AUTOSAR XML (schema 00051)
standard types defined: UINT8, UINT16, UINT32, UINT64
package /Clusters
  can cluster CANFD_F: baudrate=500000, can-fd-baudrate=2000000
    can physical channel CANFD_F_CH
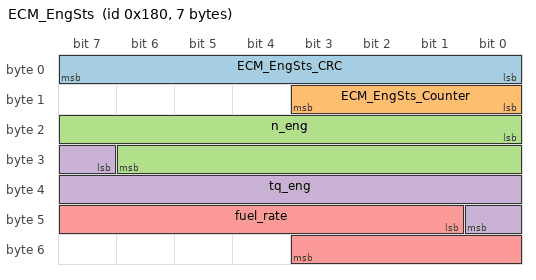
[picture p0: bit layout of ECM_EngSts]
      frame ECM_EngSts: id 0x180, from ECM, frame-length=7, can-addressing-mode=STANDARD, can-frame-rx-behavior=CAN-FD, can-frame-tx-behavior=CAN-FD
        pdu ECM_EngSts: length=7, minimum-delay=0.002, transmission-mode-true-timing={cyclic-timing=time-period=0.01, event-controlled-timing=number-of-repetitions=0}, unused-bit-pattern=255
          signal ECM_EngSts_CRC: start 0, 8 bit, little-endian, init-value=0, base-type=UINT8, transfer-property=PENDING
          signal ECM_EngSts_Counter: start 8, 4 bit, little-endian, init-value=0, base-type=UINT8, transfer-property=PENDING
          signal n_eng: start 16, 15 bit, little-endian, init-value=0, base-type=UINT16, compu {phys=raw*0.25 for raw 0..32767; unit rpm}, unit=rpm, transfer-property=TRIGGERED-ON-CHANGE
          signal tq_eng: start 31, 10 bit, little-endian, init-value=0, base-type=UINT16, compu {phys=raw*0.5-50 for raw 0..1023; unit N m}, unit=N m, transfer-property=TRIGGERED-ON-CHANGE
          signal fuel_rate: start 41, 11 bit, little-endian, init-value=0, base-type=UINT16, compu {phys=raw*0.01 for raw 0..2047; unit g/s}, unit=g/s, transfer-property=TRIGGERED-ON-CHANGE
      frame ECM_EngThm: id 0x182, from ECM, frame-length=2, can-addressing-mode=STANDARD, can-frame-rx-behavior=CAN-FD, can-frame-tx-behavior=CAN-FD
        pdu ECM_EngThm: length=2, transmission-mode-true-timing=cyclic-timing=time-period=0.1, unused-bit-pattern=255
          signal T_cool_eng: start 0, 8 bit, little-endian, init-value=0, base-type=UINT8, compu {phys=raw-40 for raw 0..255; unit degC}, unit=degC, transfer-property=PENDING
          signal T_cat: start 8, 8 bit, little-endian, init-value=0, base-type=UINT8, compu {phys=raw*5-40 for raw 0..255; unit degC}, unit=degC, transfer-property=PENDING
      frame PCU_MgSts: id 0x140, from PCU, frame-length=12, can-addressing-mode=STANDARD, can-frame-rx-behavior=CAN-FD, can-frame-tx-behavior=CAN-FD
        pdu PCU_MgSts: length=12, minimum-delay=0.002, transmission-mode-true-timing={cyclic-timing=time-period=0.01, event-controlled-timing=number-of-repetitions=0}, unused-bit-pattern=255
          signal PCU_MgSts_CRC: start 0, 8 bit, little-endian, init-value=0, base-type=UINT8, transfer-property=PENDING
          signal PCU_MgSts_Counter: start 8, 4 bit, little-endian, init-value=0, base-type=UINT8, transfer-property=PENDING
          signal n_MG1: start 16, 15 bit, little-endian, init-value=0, base-type=UINT16, compu {phys=raw-15000 for raw 0..32767; unit rpm}, unit=rpm, transfer-property=TRIGGERED-ON-CHANGE
          signal tq_MG1: start 31, 11 bit, little-endian, init-value=0, base-type=UINT16, compu {phys=raw*0.25-200 for raw 0..2047; unit N m}, unit=N m, transfer-property=TRIGGERED-ON-CHANGE
          signal n_MG2: start 42, 15 bit, little-endian, init-value=0, base-type=UINT16, compu {phys=raw-15000 for raw 0..32767; unit rpm}, unit=rpm, transfer-property=TRIGGERED-ON-CHANGE
          signal tq_MG2: start 57, 12 bit, little-endian, init-value=0, base-type=UINT16, compu {phys=raw*0.25-400 for raw 0..4095; unit N m}, unit=N m, transfer-property=TRIGGERED-ON-CHANGE
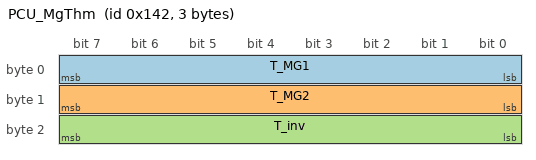
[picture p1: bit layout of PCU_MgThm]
      frame PCU_MgThm: id 0x142, from PCU, frame-length=3, can-addressing-mode=STANDARD, can-frame-rx-behavior=CAN-FD, can-frame-tx-behavior=CAN-FD
        pdu PCU_MgThm: length=3, transmission-mode-true-timing=cyclic-timing=time-period=0.1, unused-bit-pattern=255
          signal T_MG1: start 0, 8 bit, little-endian, init-value=0, base-type=UINT8, compu {phys=raw-40 for raw 0..255; unit degC}, unit=degC, transfer-property=PENDING
          signal T_MG2: start 8, 8 bit, little-endian, init-value=0, base-type=UINT8, compu {phys=raw-40 for raw 0..255; unit degC}, unit=degC, transfer-property=PENDING
          signal T_inv: start 16, 8 bit, little-endian, init-value=0, base-type=UINT8, compu {phys=raw-40 for raw 0..255; unit degC}, unit=degC, transfer-property=PENDING
      frame ESC_VehDyn: id 0x80, from ESC, frame-length=12, can-addressing-mode=STANDARD, can-frame-rx-behavior=CAN-FD, can-frame-tx-behavior=CAN-FD
        pdu ESC_VehDyn: length=12, transmission-mode-true-timing=cyclic-timing=time-period=0.01, unused-bit-pattern=255
          signal ESC_VehDyn_CRC: start 0, 8 bit, little-endian, init-value=0, base-type=UINT8, transfer-property=PENDING
          signal ESC_VehDyn_Counter: start 8, 4 bit, little-endian, init-value=0, base-type=UINT8, transfer-property=PENDING
          signal v_veh: start 16, 13 bit, little-endian, init-value=0, base-type=UINT16, compu {phys=raw*0.01 for raw 0..8191; unit m/s}, unit=m/s, transfer-property=PENDING
          signal a_long: start 29, 12 bit, little-endian, init-value=0, base-type=UINT16, compu {phys=raw*0.01-15 for raw 0..4095; unit m/s^2}, unit=m/s^2, transfer-property=PENDING
          signal a_lat: start 41, 12 bit, little-endian, init-value=0, base-type=UINT16, compu {phys=raw*0.01-15 for raw 0..4095; unit m/s^2}, unit=m/s^2, transfer-property=PENDING
          signal yaw_rate: start 53, 13 bit, little-endian, init-value=0, base-type=UINT16, compu {phys=raw*0.05-150 for raw 0..8191; unit deg/s}, unit=deg/s, transfer-property=PENDING
      frame ESC_WhlSpd: id 0x82, from ESC, frame-length=12, can-addressing-mode=STANDARD, can-frame-rx-behavior=CAN-FD, can-frame-tx-behavior=CAN-FD
        pdu ESC_WhlSpd: length=12, transmission-mode-true-timing=cyclic-timing=time-period=0.01, unused-bit-pattern=255
          signal ESC_WhlSpd_CRC: start 0, 8 bit, little-endian, init-value=0, base-type=UINT8, transfer-property=PENDING
          signal ESC_WhlSpd_Counter: start 8, 4 bit, little-endian, init-value=0, base-type=UINT8, transfer-property=PENDING
          signal w_FL: start 16, 14 bit, little-endian, init-value=0, base-type=UINT16, compu {phys=raw*0.03 for raw 0..16383; unit rad/s}, unit=rad/s, transfer-property=PENDING
          signal w_FR: start 30, 14 bit, little-endian, init-value=0, base-type=UINT16, compu {phys=raw*0.03 for raw 0..16383; unit rad/s}, unit=rad/s, transfer-property=PENDING
          signal w_RL: start 44, 14 bit, little-endian, init-value=0, base-type=UINT16, compu {phys=raw*0.03 for raw 0..16383; unit rad/s}, unit=rad/s, transfer-property=PENDING
          signal w_RR: start 58, 14 bit, little-endian, init-value=0, base-type=UINT16, compu {phys=raw*0.03 for raw 0..16383; unit rad/s}, unit=rad/s, transfer-property=PENDING
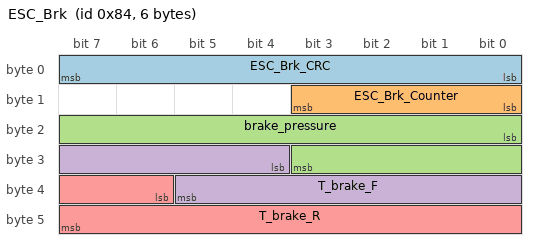
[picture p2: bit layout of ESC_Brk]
      frame ESC_Brk: id 0x84, from ESC, frame-length=6, can-addressing-mode=STANDARD, can-frame-rx-behavior=CAN-FD, can-frame-tx-behavior=CAN-FD
        pdu ESC_Brk: length=6, minimum-delay=0.005, transmission-mode-true-timing={cyclic-timing=time-period=0.02, event-controlled-timing=number-of-repetitions=0}, unused-bit-pattern=255
          signal ESC_Brk_CRC: start 0, 8 bit, little-endian, init-value=0, base-type=UINT8, transfer-property=PENDING
          signal ESC_Brk_Counter: start 8, 4 bit, little-endian, init-value=0, base-type=UINT8, transfer-property=PENDING
          signal brake_pressure: start 16, 12 bit, little-endian, init-value=0, base-type=UINT16, compu {phys=raw*0.1 for raw 0..4095; unit bar}, unit=bar, transfer-property=TRIGGERED-ON-CHANGE
          signal T_brake_F: start 28, 10 bit, little-endian, init-value=0, base-type=UINT16, compu {phys=raw-40 for raw 0..1023; unit degC}, unit=degC, transfer-property=TRIGGERED-ON-CHANGE
          signal T_brake_R: start 38, 10 bit, little-endian, init-value=0, base-type=UINT16, compu {phys=raw-40 for raw 0..1023; unit degC}, unit=degC, transfer-property=TRIGGERED-ON-CHANGE
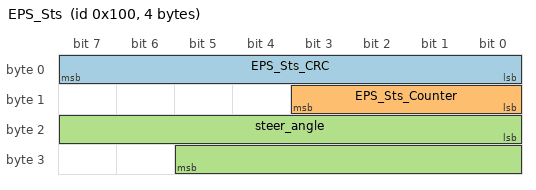
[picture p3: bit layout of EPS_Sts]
      frame EPS_Sts: id 0x100, from EPS, frame-length=4, can-addressing-mode=STANDARD, can-frame-rx-behavior=CAN-FD, can-frame-tx-behavior=CAN-FD
        pdu EPS_Sts: length=4, transmission-mode-true-timing=cyclic-timing=time-period=0.01, unused-bit-pattern=255
          signal EPS_Sts_CRC: start 0, 8 bit, little-endian, init-value=0, base-type=UINT8, transfer-property=PENDING
          signal EPS_Sts_Counter: start 8, 4 bit, little-endian, init-value=0, base-type=UINT8, transfer-property=PENDING
          signal steer_angle: start 16, 14 bit, little-endian, init-value=0, base-type=UINT16, compu {phys=raw*0.1-800 for raw 0..16383; unit deg}, unit=deg, transfer-property=PENDING
      frame DCDC_Sts: id 0x300, from DCDC_ECU, frame-length=3, can-addressing-mode=STANDARD, can-frame-rx-behavior=CAN-FD, can-frame-tx-behavior=CAN-FD
        pdu DCDC_Sts: length=3, minimum-delay=0.01, transmission-mode-true-timing={cyclic-timing=time-period=0.1, event-controlled-timing=number-of-repetitions=0}, unused-bit-pattern=255
          signal V_12: start 0, 11 bit, little-endian, init-value=0, base-type=UINT16, compu {phys=raw*0.01 for raw 0..2047; unit V}, unit=V, transfer-property=TRIGGERED-ON-CHANGE
          signal I_dcdc: start 11, 12 bit, little-endian, init-value=0, base-type=UINT16, compu {phys=raw*0.1 for raw 0..4095; unit A}, unit=A, transfer-property=TRIGGERED-ON-CHANGE
      frame TMS_Sts: id 0x340, from TMS, frame-length=3, can-addressing-mode=STANDARD, can-frame-rx-behavior=CAN-FD, can-frame-tx-behavior=CAN-FD
        pdu TMS_Sts: length=3, transmission-mode-true-timing=cyclic-timing=time-period=0.1, unused-bit-pattern=255
          signal T_cool_edu: start 0, 9 bit, little-endian, init-value=0, base-type=UINT16, compu {phys=raw*0.5-40 for raw 0..511; unit degC}, unit=degC, transfer-property=PENDING
          signal T_rad_out: start 9, 8 bit, little-endian, init-value=0, base-type=UINT8, compu {phys=raw-40 for raw 0..255; unit degC}, unit=degC, transfer-property=PENDING
      frame ZCF_TqReqEng: id 0xC0, from ZC_FRONT, frame-length=8, can-addressing-mode=STANDARD, can-frame-rx-behavior=CAN-FD, can-frame-tx-behavior=CAN-FD
        pdu ZCF_TqReqEng: length=8, transmission-mode-true-timing=cyclic-timing=time-period=0.01, unused-bit-pattern=255
          signal ZCF_TqReqEng_CRC: start 0, 8 bit, little-endian, init-value=0, base-type=UINT8, transfer-property=PENDING
          signal ZCF_TqReqEng_Counter: start 8, 4 bit, little-endian, init-value=0, base-type=UINT8, transfer-property=PENDING
      frame ZCF_TqReqMg: id 0xC2, from ZC_FRONT, frame-length=8, can-addressing-mode=STANDARD, can-frame-rx-behavior=CAN-FD, can-frame-tx-behavior=CAN-FD
        pdu ZCF_TqReqMg: length=8, transmission-mode-true-timing=cyclic-timing=time-period=0.01, unused-bit-pattern=255
          signal ZCF_TqReqMg_CRC: start 0, 8 bit, little-endian, init-value=0, base-type=UINT8, transfer-property=PENDING
          signal ZCF_TqReqMg_Counter: start 8, 4 bit, little-endian, init-value=0, base-type=UINT8, transfer-property=PENDING
      frame ZCF_ThmReq: id 0xC4, from ZC_FRONT, frame-length=8, can-addressing-mode=STANDARD, can-frame-rx-behavior=CAN-FD, can-frame-tx-behavior=CAN-FD
        pdu ZCF_ThmReq: length=8, transmission-mode-true-timing=cyclic-timing=time-period=0.1, unused-bit-pattern=255
          signal ZCF_ThmReq_Payload: start 0, 64 bit, little-endian, init-value=0, base-type=UINT64, transfer-property=PENDING
      frame ECM_Bg0: id 0x4AA, from ECM, frame-length=8, can-addressing-mode=STANDARD, can-frame-rx-behavior=CAN-FD, can-frame-tx-behavior=CAN-FD
        pdu ECM_Bg0: length=8, transmission-mode-true-timing=cyclic-timing=time-period=0.2, unused-bit-pattern=255
          signal ECM_Bg0_Payload: start 0, 64 bit, little-endian, init-value=0, base-type=UINT64, transfer-property=PENDING
      frame ECM_Bg1: id 0x196, from ECM, frame-length=24, can-addressing-mode=STANDARD, can-frame-rx-behavior=CAN-FD, can-frame-tx-behavior=CAN-FD
        pdu ECM_Bg1: length=24, transmission-mode-true-timing=cyclic-timing=time-period=0.01, unused-bit-pattern=255
          signal ECM_Bg1_Payload: start 0, 64 bit, little-endian, init-value=0, base-type=UINT64, transfer-property=PENDING
      frame ECM_Bg2: id 0x198, from ECM, frame-length=16, can-addressing-mode=STANDARD, can-frame-rx-behavior=CAN-FD, can-frame-tx-behavior=CAN-FD
        pdu ECM_Bg2: length=16, transmission-mode-true-timing=cyclic-timing=time-period=0.05, unused-bit-pattern=255
          signal ECM_Bg2_Payload: start 0, 64 bit, little-endian, init-value=0, base-type=UINT64, transfer-property=PENDING
      frame ECM_Bg3: id 0x19A, from ECM, frame-length=16, can-addressing-mode=STANDARD, can-frame-rx-behavior=CAN-FD, can-frame-tx-behavior=CAN-FD
        pdu ECM_Bg3: length=16, transmission-mode-true-timing=cyclic-timing=time-period=0.01, unused-bit-pattern=255
          signal ECM_Bg3_Payload: start 0, 64 bit, little-endian, init-value=0, base-type=UINT64, transfer-property=PENDING
      frame ECM_Bg4: id 0x4B2, from ECM, frame-length=16, can-addressing-mode=STANDARD, can-frame-rx-behavior=CAN-FD, can-frame-tx-behavior=CAN-FD
        pdu ECM_Bg4: length=16, transmission-mode-true-timing=cyclic-timing=time-period=0.1, unused-bit-pattern=255
          signal ECM_Bg4_Payload: start 0, 64 bit, little-endian, init-value=0, base-type=UINT64, transfer-property=PENDING
      frame ECM_Bg5: id 0x4B4, from ECM, frame-length=32, can-addressing-mode=STANDARD, can-frame-rx-behavior=CAN-FD, can-frame-tx-behavior=CAN-FD
        pdu ECM_Bg5: length=32, transmission-mode-true-timing=cyclic-timing=time-period=0.2, unused-bit-pattern=255
          signal ECM_Bg5_Payload: start 0, 64 bit, little-endian, init-value=0, base-type=UINT64, transfer-property=PENDING
      frame ECM_Bg6: id 0x4B6, from ECM, frame-length=64, can-addressing-mode=STANDARD, can-frame-rx-behavior=CAN-FD, can-frame-tx-behavior=CAN-FD
        pdu ECM_Bg6: length=64, transmission-mode-true-timing=cyclic-timing=time-period=0.1, unused-bit-pattern=255
          signal ECM_Bg6_Payload: start 0, 64 bit, little-endian, init-value=0, base-type=UINT64, transfer-property=PENDING
      frame ECM_NM: id 0x700, from ECM, frame-length=8, can-addressing-mode=STANDARD, can-frame-rx-behavior=CAN-FD, can-frame-tx-behavior=CAN-FD
        pdu ECM_NM: length=8, transmission-mode-true-timing=cyclic-timing=time-period=1, unused-bit-pattern=255
          signal ECM_NM_Payload: start 0, 64 bit, little-endian, init-value=0, base-type=UINT64, transfer-property=PENDING
      frame PCU_Bg0: id 0x4BA, from PCU, frame-length=8, can-addressing-mode=STANDARD, can-frame-rx-behavior=CAN-FD, can-frame-tx-behavior=CAN-FD
        pdu PCU_Bg0: length=8, transmission-mode-true-timing=cyclic-timing=time-period=0.2, unused-bit-pattern=255
          signal PCU_Bg0_Payload: start 0, 64 bit, little-endian, init-value=0, base-type=UINT64, transfer-property=PENDING
      frame PCU_Bg1: id 0x4BC, from PCU, frame-length=24, can-addressing-mode=STANDARD, can-frame-rx-behavior=CAN-FD, can-frame-tx-behavior=CAN-FD
        pdu PCU_Bg1: length=24, transmission-mode-true-timing=cyclic-timing=time-period=0.5, unused-bit-pattern=255
          signal PCU_Bg1_Payload: start 0, 64 bit, little-endian, init-value=0, base-type=UINT64, transfer-property=PENDING
      frame PCU_Bg2: id 0x158, from PCU, frame-length=8, can-addressing-mode=STANDARD, can-frame-rx-behavior=CAN-FD, can-frame-tx-behavior=CAN-FD
        pdu PCU_Bg2: length=8, transmission-mode-true-timing=cyclic-timing=time-period=0.01, unused-bit-pattern=255
          signal PCU_Bg2_Payload: start 0, 64 bit, little-endian, init-value=0, base-type=UINT64, transfer-property=PENDING
      frame PCU_Bg3: id 0x15A, from PCU, frame-length=64, can-addressing-mode=STANDARD, can-frame-rx-behavior=CAN-FD, can-frame-tx-behavior=CAN-FD
        pdu PCU_Bg3: length=64, transmission-mode-true-timing=cyclic-timing=time-period=0.02, unused-bit-pattern=255
          signal PCU_Bg3_Payload: start 0, 64 bit, little-endian, init-value=0, base-type=UINT64, transfer-property=PENDING
      frame PCU_Bg4: id 0x4C2, from PCU, frame-length=64, can-addressing-mode=STANDARD, can-frame-rx-behavior=CAN-FD, can-frame-tx-behavior=CAN-FD
        pdu PCU_Bg4: length=64, transmission-mode-true-timing=cyclic-timing=time-period=0.2, unused-bit-pattern=255
          signal PCU_Bg4_Payload: start 0, 64 bit, little-endian, init-value=0, base-type=UINT64, transfer-property=PENDING
      frame PCU_Bg5: id 0x15E, from PCU, frame-length=24, can-addressing-mode=STANDARD, can-frame-rx-behavior=CAN-FD, can-frame-tx-behavior=CAN-FD
        pdu PCU_Bg5: length=24, transmission-mode-true-timing=cyclic-timing=time-period=0.02, unused-bit-pattern=255
          signal PCU_Bg5_Payload: start 0, 64 bit, little-endian, init-value=0, base-type=UINT64, transfer-property=PENDING
      frame PCU_NM: id 0x701, from PCU, frame-length=8, can-addressing-mode=STANDARD, can-frame-rx-behavior=CAN-FD, can-frame-tx-behavior=CAN-FD
        pdu PCU_NM: length=8, transmission-mode-true-timing=cyclic-timing=time-period=1, unused-bit-pattern=255
          signal PCU_NM_Payload: start 0, 64 bit, little-endian, init-value=0, base-type=UINT64, transfer-property=PENDING
      frame ESC_Bg0: id 0x4C8, from ESC, frame-length=32, can-addressing-mode=STANDARD, can-frame-rx-behavior=CAN-FD, can-frame-tx-behavior=CAN-FD
        pdu ESC_Bg0: length=32, transmission-mode-true-timing=cyclic-timing=time-period=0.1, unused-bit-pattern=255
          signal ESC_Bg0_Payload: start 0, 64 bit, little-endian, init-value=0, base-type=UINT64, transfer-property=PENDING
      frame ESC_Bg1: id 0x98, from ESC, frame-length=24, can-addressing-mode=STANDARD, can-frame-rx-behavior=CAN-FD, can-frame-tx-behavior=CAN-FD
        pdu ESC_Bg1: length=24, transmission-mode-true-timing=cyclic-timing=time-period=0.01, unused-bit-pattern=255
          signal ESC_Bg1_Payload: start 0, 64 bit, little-endian, init-value=0, base-type=UINT64, transfer-property=PENDING
      frame ESC_Bg2: id 0x4CC, from ESC, frame-length=32, can-addressing-mode=STANDARD, can-frame-rx-behavior=CAN-FD, can-frame-tx-behavior=CAN-FD
        pdu ESC_Bg2: length=32, transmission-mode-true-timing=cyclic-timing=time-period=0.1, unused-bit-pattern=255
          signal ESC_Bg2_Payload: start 0, 64 bit, little-endian, init-value=0, base-type=UINT64, transfer-property=PENDING
      frame ESC_Bg3: id 0x4CE, from ESC, frame-length=16, can-addressing-mode=STANDARD, can-frame-rx-behavior=CAN-FD, can-frame-tx-behavior=CAN-FD
        pdu ESC_Bg3: length=16, transmission-mode-true-timing=cyclic-timing=time-period=0.1, unused-bit-pattern=255
          signal ESC_Bg3_Payload: start 0, 64 bit, little-endian, init-value=0, base-type=UINT64, transfer-property=PENDING
      frame ESC_Bg4: id 0x4D0, from ESC, frame-length=16, can-addressing-mode=STANDARD, can-frame-rx-behavior=CAN-FD, can-frame-tx-behavior=CAN-FD
        pdu ESC_Bg4: length=16, transmission-mode-true-timing=cyclic-timing=time-period=0.1, unused-bit-pattern=255
          signal ESC_Bg4_Payload: start 0, 64 bit, little-endian, init-value=0, base-type=UINT64, transfer-property=PENDING
      frame ESC_Bg5: id 0xA0, from ESC, frame-length=8, can-addressing-mode=STANDARD, can-frame-rx-behavior=CAN-FD, can-frame-tx-behavior=CAN-FD
        pdu ESC_Bg5: length=8, transmission-mode-true-timing=cyclic-timing=time-period=0.02, unused-bit-pattern=255
          signal ESC_Bg5_Payload: start 0, 64 bit, little-endian, init-value=0, base-type=UINT64, transfer-property=PENDING
      frame ESC_Bg6: id 0xA2, from ESC, frame-length=8, can-addressing-mode=STANDARD, can-frame-rx-behavior=CAN-FD, can-frame-tx-behavior=CAN-FD
        pdu ESC_Bg6: length=8, transmission-mode-true-timing=cyclic-timing=time-period=0.02, unused-bit-pattern=255
          signal ESC_Bg6_Payload: start 0, 64 bit, little-endian, init-value=0, base-type=UINT64, transfer-property=PENDING
      frame ESC_Bg7: id 0x4D6, from ESC, frame-length=24, can-addressing-mode=STANDARD, can-frame-rx-behavior=CAN-FD, can-frame-tx-behavior=CAN-FD
        pdu ESC_Bg7: length=24, transmission-mode-true-timing=cyclic-timing=time-period=0.2, unused-bit-pattern=255
          signal ESC_Bg7_Payload: start 0, 64 bit, little-endian, init-value=0, base-type=UINT64, transfer-property=PENDING
      frame ESC_NM: id 0x702, from ESC, frame-length=8, can-addressing-mode=STANDARD, can-frame-rx-behavior=CAN-FD, can-frame-tx-behavior=CAN-FD
        pdu ESC_NM: length=8, transmission-mode-true-timing=cyclic-timing=time-period=1, unused-bit-pattern=255
          signal ESC_NM_Payload: start 0, 64 bit, little-endian, init-value=0, base-type=UINT64, transfer-property=PENDING
      frame EPS_Bg0: id 0x112, from EPS, frame-length=16, can-addressing-mode=STANDARD, can-frame-rx-behavior=CAN-FD, can-frame-tx-behavior=CAN-FD
        pdu EPS_Bg0: length=16, transmission-mode-true-timing=cyclic-timing=time-period=0.01, unused-bit-pattern=255
          signal EPS_Bg0_Payload: start 0, 64 bit, little-endian, init-value=0, base-type=UINT64, transfer-property=PENDING
      frame EPS_Bg1: id 0x114, from EPS, frame-length=24, can-addressing-mode=STANDARD, can-frame-rx-behavior=CAN-FD, can-frame-tx-behavior=CAN-FD
        pdu EPS_Bg1: length=24, transmission-mode-true-timing=cyclic-timing=time-period=0.02, unused-bit-pattern=255
          signal EPS_Bg1_Payload: start 0, 64 bit, little-endian, init-value=0, base-type=UINT64, transfer-property=PENDING
      frame EPS_Bg2: id 0x4DE, from EPS, frame-length=8, can-addressing-mode=STANDARD, can-frame-rx-behavior=CAN-FD, can-frame-tx-behavior=CAN-FD
        pdu EPS_Bg2: length=8, transmission-mode-true-timing=cyclic-timing=time-period=0.2, unused-bit-pattern=255
          signal EPS_Bg2_Payload: start 0, 64 bit, little-endian, init-value=0, base-type=UINT64, transfer-property=PENDING
      frame EPS_Bg3: id 0x4E0, from EPS, frame-length=16, can-addressing-mode=STANDARD, can-frame-rx-behavior=CAN-FD, can-frame-tx-behavior=CAN-FD
        pdu EPS_Bg3: length=16, transmission-mode-true-timing=cyclic-timing=time-period=0.1, unused-bit-pattern=255
          signal EPS_Bg3_Payload: start 0, 64 bit, little-endian, init-value=0, base-type=UINT64, transfer-property=PENDING
      frame EPS_NM: id 0x703, from EPS, frame-length=8, can-addressing-mode=STANDARD, can-frame-rx-behavior=CAN-FD, can-frame-tx-behavior=CAN-FD
        pdu EPS_NM: length=8, transmission-mode-true-timing=cyclic-timing=time-period=1, unused-bit-pattern=255
          signal EPS_NM_Payload: start 0, 64 bit, little-endian, init-value=0, base-type=UINT64, transfer-property=PENDING
      frame DCDC_ECU_Bg0: id 0x4E4, from DCDC_ECU, frame-length=16, can-addressing-mode=STANDARD, can-frame-rx-behavior=CAN-FD, can-frame-tx-behavior=CAN-FD
        pdu DCDC_ECU_Bg0: length=16, transmission-mode-true-timing=cyclic-timing=time-period=0.5, unused-bit-pattern=255
          signal DCDC_ECU_Bg0_Payload: start 0, 64 bit, little-endian, init-value=0, base-type=UINT64, transfer-property=PENDING
      frame DCDC_ECU_Bg1: id 0x314, from DCDC_ECU, frame-length=8, can-addressing-mode=STANDARD, can-frame-rx-behavior=CAN-FD, can-frame-tx-behavior=CAN-FD
        pdu DCDC_ECU_Bg1: length=8, transmission-mode-true-timing=cyclic-timing=time-period=0.02, unused-bit-pattern=255
          signal DCDC_ECU_Bg1_Payload: start 0, 64 bit, little-endian, init-value=0, base-type=UINT64, transfer-property=PENDING
      frame DCDC_ECU_Bg2: id 0x4E8, from DCDC_ECU, frame-length=24, can-addressing-mode=STANDARD, can-frame-rx-behavior=CAN-FD, can-frame-tx-behavior=CAN-FD
        pdu DCDC_ECU_Bg2: length=24, transmission-mode-true-timing=cyclic-timing=time-period=0.1, unused-bit-pattern=255
          signal DCDC_ECU_Bg2_Payload: start 0, 64 bit, little-endian, init-value=0, base-type=UINT64, transfer-property=PENDING
      frame DCDC_ECU_NM: id 0x704, from DCDC_ECU, frame-length=8, can-addressing-mode=STANDARD, can-frame-rx-behavior=CAN-FD, can-frame-tx-behavior=CAN-FD
        pdu DCDC_ECU_NM: length=8, transmission-mode-true-timing=cyclic-timing=time-period=1, unused-bit-pattern=255
          signal DCDC_ECU_NM_Payload: start 0, 64 bit, little-endian, init-value=0, base-type=UINT64, transfer-property=PENDING
      frame TMS_Bg0: id 0x352, from TMS, frame-length=16, can-addressing-mode=STANDARD, can-frame-rx-behavior=CAN-FD, can-frame-tx-behavior=CAN-FD
        pdu TMS_Bg0: length=16, transmission-mode-true-timing=cyclic-timing=time-period=0.05, unused-bit-pattern=255
          signal TMS_Bg0_Payload: start 0, 64 bit, little-endian, init-value=0, base-type=UINT64, transfer-property=PENDING
      frame TMS_Bg1: id 0x4EE, from TMS, frame-length=8, can-addressing-mode=STANDARD, can-frame-rx-behavior=CAN-FD, can-frame-tx-behavior=CAN-FD
        pdu TMS_Bg1: length=8, transmission-mode-true-timing=cyclic-timing=time-period=0.1, unused-bit-pattern=255
          signal TMS_Bg1_Payload: start 0, 64 bit, little-endian, init-value=0, base-type=UINT64, transfer-property=PENDING
      frame TMS_Bg2: id 0x4F0, from TMS, frame-length=8, can-addressing-mode=STANDARD, can-frame-rx-behavior=CAN-FD, can-frame-tx-behavior=CAN-FD
        pdu TMS_Bg2: length=8, transmission-mode-true-timing=cyclic-timing=time-period=0.5, unused-bit-pattern=255
          signal TMS_Bg2_Payload: start 0, 64 bit, little-endian, init-value=0, base-type=UINT64, transfer-property=PENDING
      frame TMS_Bg3: id 0x4F2, from TMS, frame-length=64, can-addressing-mode=STANDARD, can-frame-rx-behavior=CAN-FD, can-frame-tx-behavior=CAN-FD
        pdu TMS_Bg3: length=64, transmission-mode-true-timing=cyclic-timing=time-period=0.5, unused-bit-pattern=255
          signal TMS_Bg3_Payload: start 0, 64 bit, little-endian, init-value=0, base-type=UINT64, transfer-property=PENDING
      frame TMS_NM: id 0x705, from TMS, frame-length=8, can-addressing-mode=STANDARD, can-frame-rx-behavior=CAN-FD, can-frame-tx-behavior=CAN-FD
        pdu TMS_NM: length=8, transmission-mode-true-timing=cyclic-timing=time-period=1, unused-bit-pattern=255
          signal TMS_NM_Payload: start 0, 64 bit, little-endian, init-value=0, base-type=UINT64, transfer-property=PENDING
  can cluster CANFD_R: baudrate=500000, can-fd-baudrate=2000000
    can physical channel CANFD_R_CH
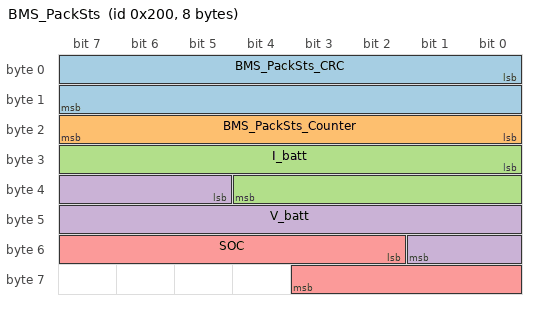
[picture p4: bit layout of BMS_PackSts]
      frame BMS_PackSts: id 0x200, from BMS, frame-length=8, can-addressing-mode=STANDARD, can-frame-rx-behavior=CAN-FD, can-frame-tx-behavior=CAN-FD
        pdu BMS_PackSts: length=8, minimum-delay=0.005, transmission-mode-true-timing={cyclic-timing=time-period=0.02, event-controlled-timing=number-of-repetitions=0}, unused-bit-pattern=255
          signal BMS_PackSts_CRC: start 0, 16 bit, little-endian, init-value=0, base-type=UINT16, transfer-property=PENDING
          signal BMS_PackSts_Counter: start 16, 8 bit, little-endian, init-value=0, base-type=UINT8, transfer-property=PENDING
          signal I_batt: start 24, 13 bit, little-endian, init-value=0, base-type=UINT16, compu {phys=raw*0.1-400 for raw 0..8191; unit A}, unit=A, transfer-property=TRIGGERED-ON-CHANGE
          signal V_batt: start 37, 13 bit, little-endian, init-value=0, base-type=UINT16, compu {phys=raw*0.1 for raw 0..8191; unit V}, unit=V, transfer-property=TRIGGERED-ON-CHANGE
          signal SOC: start 50, 10 bit, little-endian, init-value=0, base-type=UINT16, compu {phys=raw*0.1 for raw 0..1023; unit %}, unit=%, transfer-property=TRIGGERED-ON-CHANGE
      frame BMS_Thm: id 0x202, from BMS, frame-length=2, can-addressing-mode=STANDARD, can-frame-rx-behavior=CAN-FD, can-frame-tx-behavior=CAN-FD
        pdu BMS_Thm: length=2, transmission-mode-true-timing=cyclic-timing=time-period=0.1, unused-bit-pattern=255
          signal T_batt: start 0, 9 bit, little-endian, init-value=0, base-type=UINT16, compu {phys=raw*0.5-40 for raw 0..511; unit degC}, unit=degC, transfer-property=PENDING
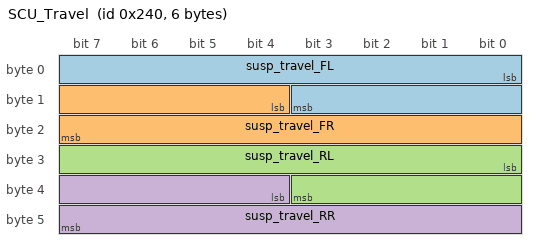
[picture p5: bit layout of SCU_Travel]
      frame SCU_Travel: id 0x240, from SCU, frame-length=6, can-addressing-mode=STANDARD, can-frame-rx-behavior=CAN-FD, can-frame-tx-behavior=CAN-FD
        pdu SCU_Travel: length=6, transmission-mode-true-timing=cyclic-timing=time-period=0.01, unused-bit-pattern=255
          signal susp_travel_FL: start 0, 12 bit, little-endian, init-value=0, base-type=UINT16, compu {phys=raw*0.1-120 for raw 0..4095; unit mm}, unit=mm, transfer-property=PENDING
          signal susp_travel_FR: start 12, 12 bit, little-endian, init-value=0, base-type=UINT16, compu {phys=raw*0.1-120 for raw 0..4095; unit mm}, unit=mm, transfer-property=PENDING
          signal susp_travel_RL: start 24, 12 bit, little-endian, init-value=0, base-type=UINT16, compu {phys=raw*0.1-120 for raw 0..4095; unit mm}, unit=mm, transfer-property=PENDING
          signal susp_travel_RR: start 36, 12 bit, little-endian, init-value=0, base-type=UINT16, compu {phys=raw*0.1-120 for raw 0..4095; unit mm}, unit=mm, transfer-property=PENDING
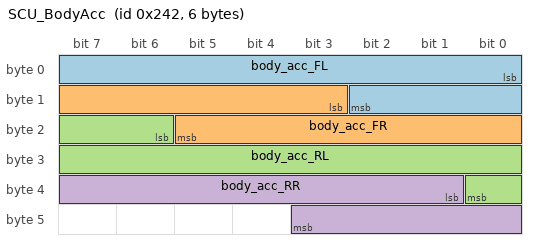
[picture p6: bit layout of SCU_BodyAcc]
      frame SCU_BodyAcc: id 0x242, from SCU, frame-length=6, can-addressing-mode=STANDARD, can-frame-rx-behavior=CAN-FD, can-frame-tx-behavior=CAN-FD
        pdu SCU_BodyAcc: length=6, transmission-mode-true-timing=cyclic-timing=time-period=0.02, unused-bit-pattern=255
          signal body_acc_FL: start 0, 11 bit, little-endian, init-value=0, base-type=UINT16, compu {phys=raw*0.01 for raw 0..2047; unit m/s^2 rms}, unit=m/s^2 rms, transfer-property=PENDING
          signal body_acc_FR: start 11, 11 bit, little-endian, init-value=0, base-type=UINT16, compu {phys=raw*0.01 for raw 0..2047; unit m/s^2 rms}, unit=m/s^2 rms, transfer-property=PENDING
          signal body_acc_RL: start 22, 11 bit, little-endian, init-value=0, base-type=UINT16, compu {phys=raw*0.01 for raw 0..2047; unit m/s^2 rms}, unit=m/s^2 rms, transfer-property=PENDING
          signal body_acc_RR: start 33, 11 bit, little-endian, init-value=0, base-type=UINT16, compu {phys=raw*0.01 for raw 0..2047; unit m/s^2 rms}, unit=m/s^2 rms, transfer-property=PENDING
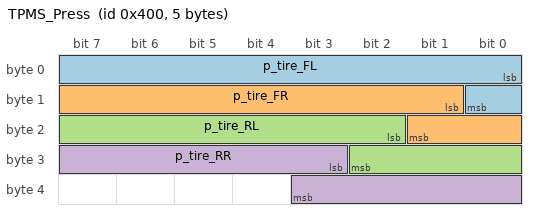
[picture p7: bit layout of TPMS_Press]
      frame TPMS_Press: id 0x400, from TPMS, frame-length=5, can-addressing-mode=STANDARD, can-frame-rx-behavior=CAN-FD, can-frame-tx-behavior=CAN-FD
        pdu TPMS_Press: length=5, minimum-delay=0.1, transmission-mode-true-timing={cyclic-timing=time-period=1, event-controlled-timing=number-of-repetitions=0}, unused-bit-pattern=255
          signal p_tire_FL: start 0, 9 bit, little-endian, init-value=0, base-type=UINT16, compu {phys=raw*0.014 for raw 0..511; unit bar}, unit=bar, transfer-property=TRIGGERED-ON-CHANGE
          signal p_tire_FR: start 9, 9 bit, little-endian, init-value=0, base-type=UINT16, compu {phys=raw*0.014 for raw 0..511; unit bar}, unit=bar, transfer-property=TRIGGERED-ON-CHANGE
          signal p_tire_RL: start 18, 9 bit, little-endian, init-value=0, base-type=UINT16, compu {phys=raw*0.014 for raw 0..511; unit bar}, unit=bar, transfer-property=TRIGGERED-ON-CHANGE
          signal p_tire_RR: start 27, 9 bit, little-endian, init-value=0, base-type=UINT16, compu {phys=raw*0.014 for raw 0..511; unit bar}, unit=bar, transfer-property=TRIGGERED-ON-CHANGE
      frame CCU_Sts: id 0x440, from CCU, frame-length=3, can-addressing-mode=STANDARD, can-frame-rx-behavior=CAN-FD, can-frame-tx-behavior=CAN-FD
        pdu CCU_Sts: length=3, minimum-delay=0.05, transmission-mode-true-timing={cyclic-timing=time-period=0.2, event-controlled-timing=number-of-repetitions=0}, unused-bit-pattern=255
          signal T_cabin: start 0, 9 bit, little-endian, init-value=0, base-type=UINT16, compu {phys=raw*0.5-40 for raw 0..511; unit degC}, unit=degC, transfer-property=TRIGGERED-ON-CHANGE
          signal P_ac: start 9, 10 bit, little-endian, init-value=0, base-type=UINT16, compu {phys=raw*10 for raw 0..1023; unit W}, unit=W, transfer-property=TRIGGERED-ON-CHANGE
      frame ZCR_BmsReq: id 0x1C0, from ZC_REAR, frame-length=8, can-addressing-mode=STANDARD, can-frame-rx-behavior=CAN-FD, can-frame-tx-behavior=CAN-FD
        pdu ZCR_BmsReq: length=8, transmission-mode-true-timing=cyclic-timing=time-period=0.02, unused-bit-pattern=255
          signal ZCR_BmsReq_CRC: start 0, 16 bit, little-endian, init-value=0, base-type=UINT16, transfer-property=PENDING
          signal ZCR_BmsReq_Counter: start 16, 8 bit, little-endian, init-value=0, base-type=UINT8, transfer-property=PENDING
      frame ZCR_ClimReq: id 0x1C2, from ZC_REAR, frame-length=8, can-addressing-mode=STANDARD, can-frame-rx-behavior=CAN-FD, can-frame-tx-behavior=CAN-FD
        pdu ZCR_ClimReq: length=8, transmission-mode-true-timing=cyclic-timing=time-period=0.2, unused-bit-pattern=255
          signal ZCR_ClimReq_Payload: start 0, 64 bit, little-endian, init-value=0, base-type=UINT64, transfer-property=PENDING
      frame BMS_Bg0: id 0x4F6, from BMS, frame-length=32, can-addressing-mode=STANDARD, can-frame-rx-behavior=CAN-FD, can-frame-tx-behavior=CAN-FD
        pdu BMS_Bg0: length=32, transmission-mode-true-timing=cyclic-timing=time-period=0.5, unused-bit-pattern=255
          signal BMS_Bg0_Payload: start 0, 64 bit, little-endian, init-value=0, base-type=UINT64, transfer-property=PENDING
      frame BMS_Bg1: id 0x4F8, from BMS, frame-length=24, can-addressing-mode=STANDARD, can-frame-rx-behavior=CAN-FD, can-frame-tx-behavior=CAN-FD
        pdu BMS_Bg1: length=24, transmission-mode-true-timing=cyclic-timing=time-period=0.1, unused-bit-pattern=255
          signal BMS_Bg1_Payload: start 0, 64 bit, little-endian, init-value=0, base-type=UINT64, transfer-property=PENDING
      frame BMS_Bg2: id 0x218, from BMS, frame-length=16, can-addressing-mode=STANDARD, can-frame-rx-behavior=CAN-FD, can-frame-tx-behavior=CAN-FD
        pdu BMS_Bg2: length=16, transmission-mode-true-timing=cyclic-timing=time-period=0.02, unused-bit-pattern=255
          signal BMS_Bg2_Payload: start 0, 64 bit, little-endian, init-value=0, base-type=UINT64, transfer-property=PENDING
      frame BMS_Bg3: id 0x4FC, from BMS, frame-length=64, can-addressing-mode=STANDARD, can-frame-rx-behavior=CAN-FD, can-frame-tx-behavior=CAN-FD
        pdu BMS_Bg3: length=64, transmission-mode-true-timing=cyclic-timing=time-period=0.1, unused-bit-pattern=255
          signal BMS_Bg3_Payload: start 0, 64 bit, little-endian, init-value=0, base-type=UINT64, transfer-property=PENDING
      frame BMS_Bg4: id 0x4FE, from BMS, frame-length=24, can-addressing-mode=STANDARD, can-frame-rx-behavior=CAN-FD, can-frame-tx-behavior=CAN-FD
        pdu BMS_Bg4: length=24, transmission-mode-true-timing=cyclic-timing=time-period=0.2, unused-bit-pattern=255
          signal BMS_Bg4_Payload: start 0, 64 bit, little-endian, init-value=0, base-type=UINT64, transfer-property=PENDING
      frame BMS_Bg5: id 0x500, from BMS, frame-length=16, can-addressing-mode=STANDARD, can-frame-rx-behavior=CAN-FD, can-frame-tx-behavior=CAN-FD
        pdu BMS_Bg5: length=16, transmission-mode-true-timing=cyclic-timing=time-period=0.1, unused-bit-pattern=255
          signal BMS_Bg5_Payload: start 0, 64 bit, little-endian, init-value=0, base-type=UINT64, transfer-property=PENDING
      frame BMS_Bg6: id 0x220, from BMS, frame-length=64, can-addressing-mode=STANDARD, can-frame-rx-behavior=CAN-FD, can-frame-tx-behavior=CAN-FD
        pdu BMS_Bg6: length=64, transmission-mode-true-timing=cyclic-timing=time-period=0.05, unused-bit-pattern=255
          signal BMS_Bg6_Payload: start 0, 64 bit, little-endian, init-value=0, base-type=UINT64, transfer-property=PENDING
      frame BMS_Bg7: id 0x222, from BMS, frame-length=8, can-addressing-mode=STANDARD, can-frame-rx-behavior=CAN-FD, can-frame-tx-behavior=CAN-FD
        pdu BMS_Bg7: length=8, transmission-mode-true-timing=cyclic-timing=time-period=0.01, unused-bit-pattern=255
          signal BMS_Bg7_Payload: start 0, 64 bit, little-endian, init-value=0, base-type=UINT64, transfer-property=PENDING
      frame BMS_Bg8: id 0x224, from BMS, frame-length=32, can-addressing-mode=STANDARD, can-frame-rx-behavior=CAN-FD, can-frame-tx-behavior=CAN-FD
        pdu BMS_Bg8: length=32, transmission-mode-true-timing=cyclic-timing=time-period=0.05, unused-bit-pattern=255
          signal BMS_Bg8_Payload: start 0, 64 bit, little-endian, init-value=0, base-type=UINT64, transfer-property=PENDING
      frame BMS_Bg9: id 0x226, from BMS, frame-length=8, can-addressing-mode=STANDARD, can-frame-rx-behavior=CAN-FD, can-frame-tx-behavior=CAN-FD
        pdu BMS_Bg9: length=8, transmission-mode-true-timing=cyclic-timing=time-period=0.05, unused-bit-pattern=255
          signal BMS_Bg9_Payload: start 0, 64 bit, little-endian, init-value=0, base-type=UINT64, transfer-property=PENDING
      frame BMS_Bg10: id 0x228, from BMS, frame-length=8, can-addressing-mode=STANDARD, can-frame-rx-behavior=CAN-FD, can-frame-tx-behavior=CAN-FD
        pdu BMS_Bg10: length=8, transmission-mode-true-timing=cyclic-timing=time-period=0.01, unused-bit-pattern=255
          signal BMS_Bg10_Payload: start 0, 64 bit, little-endian, init-value=0, base-type=UINT64, transfer-property=PENDING
      frame BMS_NM: id 0x706, from BMS, frame-length=8, can-addressing-mode=STANDARD, can-frame-rx-behavior=CAN-FD, can-frame-tx-behavior=CAN-FD
        pdu BMS_NM: length=8, transmission-mode-true-timing=cyclic-timing=time-period=1, unused-bit-pattern=255
          signal BMS_NM_Payload: start 0, 64 bit, little-endian, init-value=0, base-type=UINT64, transfer-property=PENDING
      frame SCU_Bg0: id 0x254, from SCU, frame-length=32, can-addressing-mode=STANDARD, can-frame-rx-behavior=CAN-FD, can-frame-tx-behavior=CAN-FD
        pdu SCU_Bg0: length=32, transmission-mode-true-timing=cyclic-timing=time-period=0.01, unused-bit-pattern=255
          signal SCU_Bg0_Payload: start 0, 64 bit, little-endian, init-value=0, base-type=UINT64, transfer-property=PENDING
      frame SCU_Bg1: id 0x256, from SCU, frame-length=8, can-addressing-mode=STANDARD, can-frame-rx-behavior=CAN-FD, can-frame-tx-behavior=CAN-FD
        pdu SCU_Bg1: length=8, transmission-mode-true-timing=cyclic-timing=time-period=0.05, unused-bit-pattern=255
          signal SCU_Bg1_Payload: start 0, 64 bit, little-endian, init-value=0, base-type=UINT64, transfer-property=PENDING
      frame SCU_Bg2: id 0x512, from SCU, frame-length=16, can-addressing-mode=STANDARD, can-frame-rx-behavior=CAN-FD, can-frame-tx-behavior=CAN-FD
        pdu SCU_Bg2: length=16, transmission-mode-true-timing=cyclic-timing=time-period=0.1, unused-bit-pattern=255
          signal SCU_Bg2_Payload: start 0, 64 bit, little-endian, init-value=0, base-type=UINT64, transfer-property=PENDING
      frame SCU_Bg3: id 0x514, from SCU, frame-length=24, can-addressing-mode=STANDARD, can-frame-rx-behavior=CAN-FD, can-frame-tx-behavior=CAN-FD
        pdu SCU_Bg3: length=24, transmission-mode-true-timing=cyclic-timing=time-period=0.1, unused-bit-pattern=255
          signal SCU_Bg3_Payload: start 0, 64 bit, little-endian, init-value=0, base-type=UINT64, transfer-property=PENDING
      frame SCU_Bg4: id 0x516, from SCU, frame-length=8, can-addressing-mode=STANDARD, can-frame-rx-behavior=CAN-FD, can-frame-tx-behavior=CAN-FD
        pdu SCU_Bg4: length=8, transmission-mode-true-timing=cyclic-timing=time-period=0.1, unused-bit-pattern=255
          signal SCU_Bg4_Payload: start 0, 64 bit, little-endian, init-value=0, base-type=UINT64, transfer-property=PENDING
      frame SCU_Bg5: id 0x25E, from SCU, frame-length=32, can-addressing-mode=STANDARD, can-frame-rx-behavior=CAN-FD, can-frame-tx-behavior=CAN-FD
        pdu SCU_Bg5: length=32, transmission-mode-true-timing=cyclic-timing=time-period=0.02, unused-bit-pattern=255
          signal SCU_Bg5_Payload: start 0, 64 bit, little-endian, init-value=0, base-type=UINT64, transfer-property=PENDING
      frame SCU_Bg6: id 0x51A, from SCU, frame-length=24, can-addressing-mode=STANDARD, can-frame-rx-behavior=CAN-FD, can-frame-tx-behavior=CAN-FD
        pdu SCU_Bg6: length=24, transmission-mode-true-timing=cyclic-timing=time-period=0.5, unused-bit-pattern=255
          signal SCU_Bg6_Payload: start 0, 64 bit, little-endian, init-value=0, base-type=UINT64, transfer-property=PENDING
      frame SCU_NM: id 0x707, from SCU, frame-length=8, can-addressing-mode=STANDARD, can-frame-rx-behavior=CAN-FD, can-frame-tx-behavior=CAN-FD
        pdu SCU_NM: length=8, transmission-mode-true-timing=cyclic-timing=time-period=1, unused-bit-pattern=255
          signal SCU_NM_Payload: start 0, 64 bit, little-endian, init-value=0, base-type=UINT64, transfer-property=PENDING
      frame TPMS_Bg0: id 0x51E, from TPMS, frame-length=24, can-addressing-mode=STANDARD, can-frame-rx-behavior=CAN-FD, can-frame-tx-behavior=CAN-FD
        pdu TPMS_Bg0: length=24, transmission-mode-true-timing=cyclic-timing=time-period=0.1, unused-bit-pattern=255
          signal TPMS_Bg0_Payload: start 0, 64 bit, little-endian, init-value=0, base-type=UINT64, transfer-property=PENDING
      frame TPMS_Bg1: id 0x414, from TPMS, frame-length=16, can-addressing-mode=STANDARD, can-frame-rx-behavior=CAN-FD, can-frame-tx-behavior=CAN-FD
        pdu TPMS_Bg1: length=16, transmission-mode-true-timing=cyclic-timing=time-period=0.01, unused-bit-pattern=255
          signal TPMS_Bg1_Payload: start 0, 64 bit, little-endian, init-value=0, base-type=UINT64, transfer-property=PENDING
      frame TPMS_Bg2: id 0x416, from TPMS, frame-length=16, can-addressing-mode=STANDARD, can-frame-rx-behavior=CAN-FD, can-frame-tx-behavior=CAN-FD
        pdu TPMS_Bg2: length=16, transmission-mode-true-timing=cyclic-timing=time-period=0.05, unused-bit-pattern=255
          signal TPMS_Bg2_Payload: start 0, 64 bit, little-endian, init-value=0, base-type=UINT64, transfer-property=PENDING
      frame TPMS_NM: id 0x708, from TPMS, frame-length=8, can-addressing-mode=STANDARD, can-frame-rx-behavior=CAN-FD, can-frame-tx-behavior=CAN-FD
        pdu TPMS_NM: length=8, transmission-mode-true-timing=cyclic-timing=time-period=1, unused-bit-pattern=255
          signal TPMS_NM_Payload: start 0, 64 bit, little-endian, init-value=0, base-type=UINT64, transfer-property=PENDING
      frame CCU_Bg0: id 0x526, from CCU, frame-length=16, can-addressing-mode=STANDARD, can-frame-rx-behavior=CAN-FD, can-frame-tx-behavior=CAN-FD
        pdu CCU_Bg0: length=16, transmission-mode-true-timing=cyclic-timing=time-period=0.2, unused-bit-pattern=255
          signal CCU_Bg0_Payload: start 0, 64 bit, little-endian, init-value=0, base-type=UINT64, transfer-property=PENDING
      frame CCU_Bg1: id 0x528, from CCU, frame-length=16, can-addressing-mode=STANDARD, can-frame-rx-behavior=CAN-FD, can-frame-tx-behavior=CAN-FD
        pdu CCU_Bg1: length=16, transmission-mode-true-timing=cyclic-timing=time-period=0.2, unused-bit-pattern=255
          signal CCU_Bg1_Payload: start 0, 64 bit, little-endian, init-value=0, base-type=UINT64, transfer-property=PENDING
      frame CCU_Bg2: id 0x456, from CCU, frame-length=32, can-addressing-mode=STANDARD, can-frame-rx-behavior=CAN-FD, can-frame-tx-behavior=CAN-FD
        pdu CCU_Bg2: length=32, transmission-mode-true-timing=cyclic-timing=time-period=0.01, unused-bit-pattern=255
          signal CCU_Bg2_Payload: start 0, 64 bit, little-endian, init-value=0, base-type=UINT64, transfer-property=PENDING
      frame CCU_Bg3: id 0x52C, from CCU, frame-length=24, can-addressing-mode=STANDARD, can-frame-rx-behavior=CAN-FD, can-frame-tx-behavior=CAN-FD
        pdu CCU_Bg3: length=24, transmission-mode-true-timing=cyclic-timing=time-period=0.2, unused-bit-pattern=255
          signal CCU_Bg3_Payload: start 0, 64 bit, little-endian, init-value=0, base-type=UINT64, transfer-property=PENDING
      frame CCU_Bg4: id 0x52E, from CCU, frame-length=16, can-addressing-mode=STANDARD, can-frame-rx-behavior=CAN-FD, can-frame-tx-behavior=CAN-FD
        pdu CCU_Bg4: length=16, transmission-mode-true-timing=cyclic-timing=time-period=0.5, unused-bit-pattern=255
          signal CCU_Bg4_Payload: start 0, 64 bit, little-endian, init-value=0, base-type=UINT64, transfer-property=PENDING
      frame CCU_Bg5: id 0x530, from CCU, frame-length=8, can-addressing-mode=STANDARD, can-frame-rx-behavior=CAN-FD, can-frame-tx-behavior=CAN-FD
        pdu CCU_Bg5: length=8, transmission-mode-true-timing=cyclic-timing=time-period=0.2, unused-bit-pattern=255
          signal CCU_Bg5_Payload: start 0, 64 bit, little-endian, init-value=0, base-type=UINT64, transfer-property=PENDING
      frame CCU_Bg6: id 0x45E, from CCU, frame-length=32, can-addressing-mode=STANDARD, can-frame-rx-behavior=CAN-FD, can-frame-tx-behavior=CAN-FD
        pdu CCU_Bg6: length=32, transmission-mode-true-timing=cyclic-timing=time-period=0.01, unused-bit-pattern=255
          signal CCU_Bg6_Payload: start 0, 64 bit, little-endian, init-value=0, base-type=UINT64, transfer-property=PENDING
      frame CCU_Bg7: id 0x534, from CCU, frame-length=24, can-addressing-mode=STANDARD, can-frame-rx-behavior=CAN-FD, can-frame-tx-behavior=CAN-FD
        pdu CCU_Bg7: length=24, transmission-mode-true-timing=cyclic-timing=time-period=0.5, unused-bit-pattern=255
          signal CCU_Bg7_Payload: start 0, 64 bit, little-endian, init-value=0, base-type=UINT64, transfer-property=PENDING
      frame CCU_NM: id 0x709, from CCU, frame-length=8, can-addressing-mode=STANDARD, can-frame-rx-behavior=CAN-FD, can-frame-tx-behavior=CAN-FD
        pdu CCU_NM: length=8, transmission-mode-true-timing=cyclic-timing=time-period=1, unused-bit-pattern=255
          signal CCU_NM_Payload: start 0, 64 bit, little-endian, init-value=0, base-type=UINT64, transfer-property=PENDING
package /Units
  46 x unit:
    U_n_eng: display-name=rpm
    U_tq_eng: display-name=N m
    U_fuel_rate: display-name=g/s
    U_T_cool_eng: display-name=degC
    U_T_cat: display-name=degC
    U_n_MG1: display-name=rpm
    U_tq_MG1: display-name=N m
    U_n_MG2: display-name=rpm
    U_tq_MG2: display-name=N m
    U_T_MG1: display-name=degC
    U_T_MG2: display-name=degC
    U_T_inv: display-name=degC
    U_v_veh: display-name=m/s
    U_a_long: display-name=m/s^2
    U_a_lat: display-name=m/s^2
    U_yaw_rate: display-name=deg/s
    U_w_FL: display-name=rad/s
    U_w_FR: display-name=rad/s
    U_w_RL: display-name=rad/s
    U_w_RR: display-name=rad/s
    U_brake_pressure: display-name=bar
    U_T_brake_F: display-name=degC
    U_T_brake_R: display-name=degC
    U_steer_angle: display-name=deg
    U_V_12: display-name=V
    U_I_dcdc: display-name=A
    U_T_cool_edu: display-name=degC
    U_T_rad_out: display-name=degC
    U_I_batt: display-name=A
    U_V_batt: display-name=V
    U_SOC: display-name=%
    U_T_batt: display-name=degC
    U_susp_travel_FL: display-name=mm
    U_susp_travel_FR: display-name=mm
    U_susp_travel_RL: display-name=mm
    U_susp_travel_RR: display-name=mm
    U_body_acc_FL: display-name=m/s^2 rms
    U_body_acc_FR: display-name=m/s^2 rms
    U_body_acc_RL: display-name=m/s^2 rms
    U_body_acc_RR: display-name=m/s^2 rms
    U_p_tire_FL: display-name=bar
    U_p_tire_FR: display-name=bar
    U_p_tire_RL: display-name=bar
    U_p_tire_RR: display-name=bar
    U_T_cabin: display-name=degC
    U_P_ac: display-name=W
package /ECUs
  12 x ecu instance:
    ECM: associated-com-i-pdu-group=ECM_Tx
      can communication connector CN_CANFD_F
    PCU: associated-com-i-pdu-group=PCU_Tx
      can communication connector CN_CANFD_F
    ESC: associated-com-i-pdu-group=ESC_Tx
      can communication connector CN_CANFD_F
    EPS: associated-com-i-pdu-group=EPS_Tx
      can communication connector CN_CANFD_F
    DCDC_ECU: associated-com-i-pdu-group=DCDC_ECU_Tx
      can communication connector CN_CANFD_F
    TMS: associated-com-i-pdu-group=TMS_Tx
      can communication connector CN_CANFD_F
    BMS: associated-com-i-pdu-group=BMS_Tx
      can communication connector CN_CANFD_R
    SCU: associated-com-i-pdu-group=SCU_Tx
      can communication connector CN_CANFD_R
    TPMS: associated-com-i-pdu-group=TPMS_Tx
      can communication connector CN_CANFD_R
    CCU: associated-com-i-pdu-group=CCU_Tx
      can communication connector CN_CANFD_R
    ZC_FRONT: associated-com-i-pdu-group=[ZC_FRONT_Tx, ZC_FRONT_Rx]
      can communication connector CN_CANFD_F
    ZC_REAR: associated-com-i-pdu-group=[ZC_REAR_Tx, ZC_REAR_Rx]
      can communication connector CN_CANFD_R
package /PduGroups
  14 x i signal i pdu group:
    ECM_Tx: communication-direction=OUT, i-signal-i-pdus=[ECM_EngSts, ECM_EngThm, ECM_Bg0, ECM_Bg1, ECM_Bg2, ECM_Bg3, ECM_Bg4, ECM_Bg5, ECM_Bg6, ECM_NM]
    PCU_Tx: communication-direction=OUT, i-signal-i-pdus=[PCU_MgSts, PCU_MgThm, PCU_Bg0, PCU_Bg1, PCU_Bg2, PCU_Bg3, PCU_Bg4, PCU_Bg5, PCU_NM]
    ESC_Tx: communication-direction=OUT, i-signal-i-pdus=[ESC_VehDyn, ESC_WhlSpd, ESC_Brk, ESC_Bg0, ESC_Bg1, ESC_Bg2, ESC_Bg3, ESC_Bg4, ESC_Bg5, ESC_Bg6, ESC_Bg7, ESC_NM]
    EPS_Tx: communication-direction=OUT, i-signal-i-pdus=[EPS_Sts, EPS_Bg0, EPS_Bg1, EPS_Bg2, EPS_Bg3, EPS_NM]
    DCDC_ECU_Tx: communication-direction=OUT, i-signal-i-pdus=[DCDC_Sts, DCDC_ECU_Bg0, DCDC_ECU_Bg1, DCDC_ECU_Bg2, DCDC_ECU_NM]
    TMS_Tx: communication-direction=OUT, i-signal-i-pdus=[TMS_Sts, TMS_Bg0, TMS_Bg1, TMS_Bg2, TMS_Bg3, TMS_NM]
    BMS_Tx: communication-direction=OUT
      i-signal-i-pdus:
        BMS_PackSts
        BMS_Thm
        BMS_Bg{0..10}
        BMS_NM
    SCU_Tx: communication-direction=OUT, i-signal-i-pdus=[SCU_Travel, SCU_BodyAcc, SCU_Bg0, SCU_Bg1, SCU_Bg2, SCU_Bg3, SCU_Bg4, SCU_Bg5, SCU_Bg6, SCU_NM]
    TPMS_Tx: communication-direction=OUT, i-signal-i-pdus=[TPMS_Press, TPMS_Bg0, TPMS_Bg1, TPMS_Bg2, TPMS_NM]
    CCU_Tx: communication-direction=OUT, i-signal-i-pdus=[CCU_Sts, CCU_Bg0, CCU_Bg1, CCU_Bg2, CCU_Bg3, CCU_Bg4, CCU_Bg5, CCU_Bg6, CCU_Bg7, CCU_NM]
    ZC_FRONT_Tx: communication-direction=OUT, i-signal-i-pdus=[ZCF_TqReqEng, ZCF_TqReqMg, ZCF_ThmReq]
    ZC_FRONT_Rx: communication-direction=IN, i-signal-i-pdus=[ECM_EngSts, ECM_EngThm, PCU_MgSts, PCU_MgThm, ESC_VehDyn, ESC_WhlSpd, ESC_Brk, EPS_Sts, DCDC_Sts, TMS_Sts]
    ZC_REAR_Tx: communication-direction=OUT, i-signal-i-pdus=[ZCR_BmsReq, ZCR_ClimReq]
    ZC_REAR_Rx: communication-direction=IN, i-signal-i-pdus=[BMS_PackSts, BMS_Thm, SCU_Travel, SCU_BodyAcc, TPMS_Press, CCU_Sts]
package /E2E
  end to end protection set E2E_Set
    10 x end to end protection:
      E2E_ECM_EngSts: end-to-end-profile={category=PROFILE_11, data-ids=256, max-delta-counter=1}
        end to end protection i signal i pdu E2EP_ECM_EngSts: i-signal-i-pdu=ECM_EngSts
      E2E_PCU_MgSts: end-to-end-profile={category=PROFILE_11, data-ids=257, max-delta-counter=1}
        end to end protection i signal i pdu E2EP_PCU_MgSts: i-signal-i-pdu=PCU_MgSts
      E2E_ESC_VehDyn: end-to-end-profile={category=PROFILE_11, data-ids=258, max-delta-counter=1}
        end to end protection i signal i pdu E2EP_ESC_VehDyn: i-signal-i-pdu=ESC_VehDyn
      E2E_ESC_WhlSpd: end-to-end-profile={category=PROFILE_11, data-ids=259, max-delta-counter=1}
        end to end protection i signal i pdu E2EP_ESC_WhlSpd: i-signal-i-pdu=ESC_WhlSpd
      E2E_ESC_Brk: end-to-end-profile={category=PROFILE_11, data-ids=260, max-delta-counter=1}
        end to end protection i signal i pdu E2EP_ESC_Brk: i-signal-i-pdu=ESC_Brk
      E2E_EPS_Sts: end-to-end-profile={category=PROFILE_11, data-ids=261, max-delta-counter=1}
        end to end protection i signal i pdu E2EP_EPS_Sts: i-signal-i-pdu=EPS_Sts
      E2E_BMS_PackSts: end-to-end-profile={category=PROFILE_05, data-ids=262, max-delta-counter=1}
        end to end protection i signal i pdu E2EP_BMS_PackSts: i-signal-i-pdu=BMS_PackSts
      E2E_ZCF_TqReqEng: end-to-end-profile={category=PROFILE_11, data-ids=263, max-delta-counter=1}
        end to end protection i signal i pdu E2EP_ZCF_TqReqEng: i-signal-i-pdu=ZCF_TqReqEng
      E2E_ZCF_TqReqMg: end-to-end-profile={category=PROFILE_11, data-ids=264, max-delta-counter=1}
        end to end protection i signal i pdu E2EP_ZCF_TqReqMg: i-signal-i-pdu=ZCF_TqReqMg
      E2E_ZCR_BmsReq: end-to-end-profile={category=PROFILE_05, data-ids=265, max-delta-counter=1}
        end to end protection i signal i pdu E2EP_ZCR_BmsReq: i-signal-i-pdu=ZCR_BmsReq
